VERSION ""

NS_ :

BS_:

BU_:

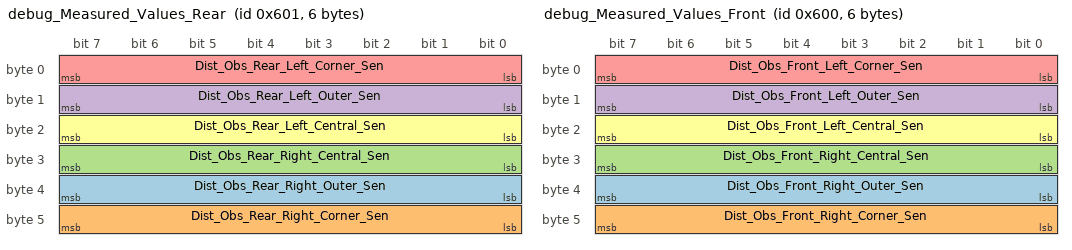
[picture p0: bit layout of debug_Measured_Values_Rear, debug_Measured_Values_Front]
BO_ 1537 debug_Measured_Values_Rear: 6 Vector__XXX
 SG_ Dist_Obs_Rear_Right_Outer_Sen : 32|8@1+ (1,0) [0|0] "" Vector__XXX
 SG_ Dist_Obs_Rear_Right_Corner_Sen : 40|8@1+ (1,0) [0|0] "" Vector__XXX
 SG_ Dist_Obs_Rear_Right_Central_Sen : 24|8@1+ (1,0) [0|0] "" Vector__XXX
 SG_ Dist_Obs_Rear_Left_Outer_Sen : 8|8@1+ (1,0) [0|0] "" Vector__XXX
 SG_ Dist_Obs_Rear_Left_Corner_Sen : 0|8@1+ (1,0) [0|0] "" Vector__XXX
 SG_ Dist_Obs_Rear_Left_Central_Sen : 16|8@1+ (1,0) [0|0] "" Vector__XXX

BO_ 1536 debug_Measured_Values_Front: 6 Vector__XXX
 SG_ Dist_Obs_Front_Right_Outer_Sen : 32|8@1+ (1,0) [0|0] "" Vector__XXX
 SG_ Dist_Obs_Front_Right_Corner_Sen : 40|8@1+ (1,0) [0|0] "" Vector__XXX
 SG_ Dist_Obs_Front_Right_Central_Sen : 24|8@1+ (1,0) [0|0] "" Vector__XXX
 SG_ Dist_Obs_Front_Left_Outer_Sen : 8|8@1+ (1,0) [0|0] "" Vector__XXX
 SG_ Dist_Obs_Front_Left_Corner_Sen : 0|8@1+ (1,0) [0|0] "" Vector__XXX
 SG_ Dist_Obs_Front_Left_Central_Sen : 16|8@1+ (1,0) [0|0] "" Vector__XXX

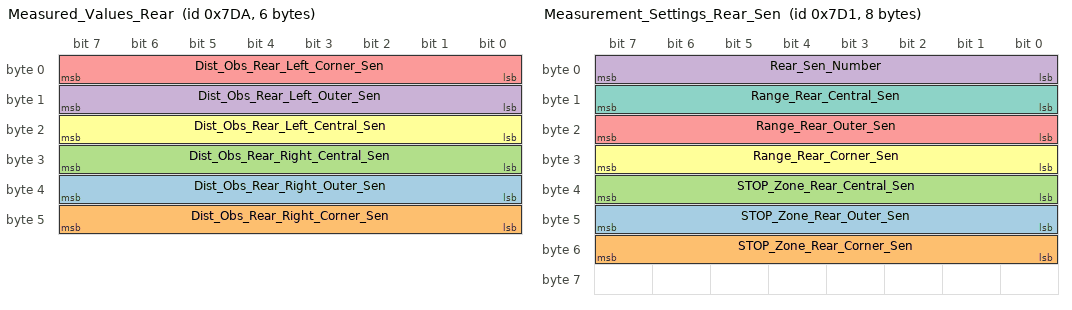
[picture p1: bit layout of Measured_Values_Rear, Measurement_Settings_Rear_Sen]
BO_ 2010 Measured_Values_Rear: 6 Vector__XXX
 SG_ Dist_Obs_Rear_Right_Outer_Sen : 32|8@1+ (1,0) [0|0] "" Vector__XXX
 SG_ Dist_Obs_Rear_Right_Corner_Sen : 40|8@1+ (1,0) [0|0] "" Vector__XXX
 SG_ Dist_Obs_Rear_Right_Central_Sen : 24|8@1+ (1,0) [0|0] "" Vector__XXX
 SG_ Dist_Obs_Rear_Left_Outer_Sen : 8|8@1+ (1,0) [0|0] "" Vector__XXX
 SG_ Dist_Obs_Rear_Left_Corner_Sen : 0|8@1+ (1,0) [0|0] "" Vector__XXX
 SG_ Dist_Obs_Rear_Left_Central_Sen : 16|8@1+ (1,0) [0|0] "" Vector__XXX

BO_ 2001 Measurement_Settings_Rear_Sen: 8 Vector__XXX
 SG_ STOP_Zone_Rear_Outer_Sen : 40|8@1+ (1,0) [0|0] "" Vector__XXX
 SG_ STOP_Zone_Rear_Corner_Sen : 48|8@1+ (1,0) [0|0] "" Vector__XXX
 SG_ STOP_Zone_Rear_Central_Sen : 32|8@1+ (1,0) [0|0] "" Vector__XXX
 SG_ Rear_Sen_Number : 0|8@1+ (1,0) [0|0] "" Vector__XXX
 SG_ Range_Rear_Outer_Sen : 16|8@1+ (1,0) [0|0] "" Vector__XXX
 SG_ Range_Rear_Corner_Sen : 24|8@1+ (1,0) [0|0] "" Vector__XXX
 SG_ Range_Rear_Central_Sen : 8|8@1+ (1,0) [0|0] "" Vector__XXX

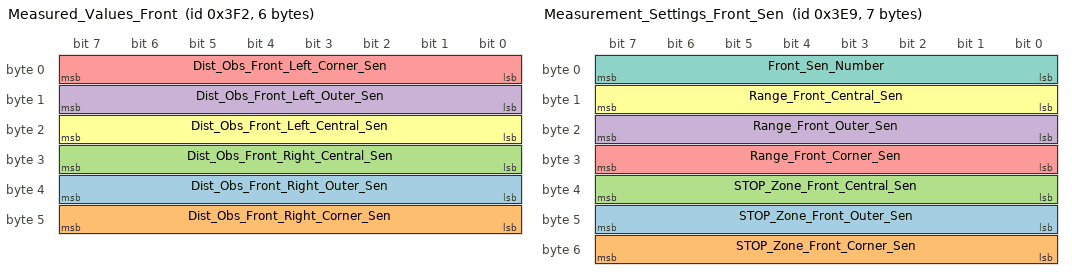
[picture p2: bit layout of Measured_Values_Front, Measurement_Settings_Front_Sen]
BO_ 1010 Measured_Values_Front: 6 Vector__XXX
 SG_ Dist_Obs_Front_Right_Outer_Sen : 32|8@1+ (1,0) [0|0] "" Vector__XXX
 SG_ Dist_Obs_Front_Right_Corner_Sen : 40|8@1+ (1,0) [0|0] "" Vector__XXX
 SG_ Dist_Obs_Front_Right_Central_Sen : 24|8@1+ (1,0) [0|0] "" Vector__XXX
 SG_ Dist_Obs_Front_Left_Outer_Sen : 8|8@1+ (1,0) [0|0] "" Vector__XXX
 SG_ Dist_Obs_Front_Left_Corner_Sen : 0|8@1+ (1,0) [0|0] "" Vector__XXX
 SG_ Dist_Obs_Front_Left_Central_Sen : 16|8@1+ (1,0) [0|0] "" Vector__XXX

BO_ 1001 Measurement_Settings_Front_Sen: 7 Vector__XXX
 SG_ STOP_Zone_Front_Outer_Sen : 40|8@1+ (1,0) [0|0] "" Vector__XXX
 SG_ STOP_Zone_Front_Corner_Sen : 48|8@1+ (1,0) [0|0] "" Vector__XXX
 SG_ STOP_Zone_Front_Central_Sen : 32|8@1+ (1,0) [0|0] "" Vector__XXX
 SG_ Range_Front_Outer_Sen : 16|8@1+ (1,0) [0|0] "" Vector__XXX
 SG_ Range_Front_Corner_Sen : 24|8@1+ (1,0) [0|0] "" Vector__XXX
 SG_ Range_Front_Central_Sen : 8|8@1+ (1,0) [0|0] "" Vector__XXX
 SG_ Front_Sen_Number : 0|8@1+ (1,0) [0|0] "" Vector__XXX

CM_ "

";
BA_DEF_  "NmAsrRepeatMessageTime" INT 0 0;
BA_DEF_  "NmAsrWaitBusSleepTime" INT 0 0;
BA_DEF_  "NmAsrTimeoutTime" INT 0 0;
BA_DEF_  "NmAsrCanMsgCycleTime" INT 0 0;
BA_DEF_  "NmAsrMessageCount" INT 0 256;
BA_DEF_ BU_  "GenNodSleepTime" INT 0 1000000;
BA_DEF_DEF_  "NmAsrRepeatMessageTime" 3200;
BA_DEF_DEF_  "NmAsrWaitBusSleepTime" 1500;
BA_DEF_DEF_  "NmAsrTimeoutTime" 2000;
BA_DEF_DEF_  "NmAsrCanMsgCycleTime" 640;
BA_DEF_DEF_  "NmAsrMessageCount" 64;
BA_DEF_DEF_  "GenNodSleepTime" 4000;
